# RSL15 register map
Vendor: ONSemiconductor; Series: RSL15 Series; File version: 1.0
CPU: CM33 r0p4, little endian, MPU, FPU, 3 interrupt priority bits
Registers are 32-bit, read-write, reset 0x0 unless marked. A register's access mark holds for its fields unless they carry their own. Offsets are from the block's base; [hi:lo] are bit positions; {n}, {i} and the like mark numbered series.

## MPU — Memory Protection Unit
Base 0xE000ED90
0x00 MPU_TYPE ro reset 0x400 — Indicates how many regions the MPU for the selected security state supports
  [15:8] NBR_OF_REGION — Number of regions
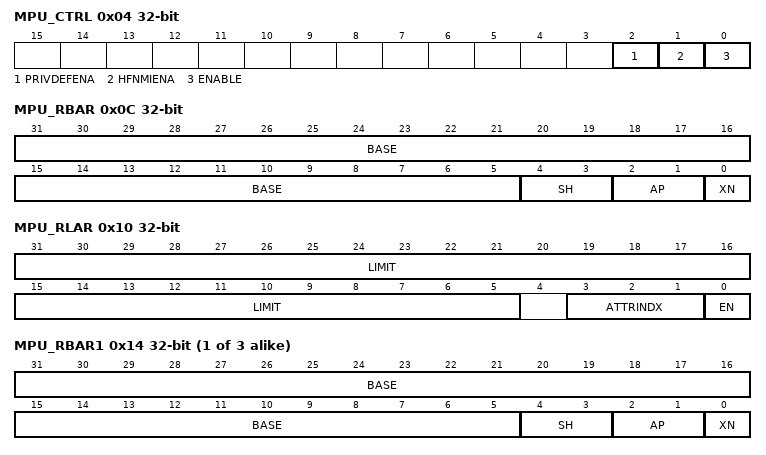
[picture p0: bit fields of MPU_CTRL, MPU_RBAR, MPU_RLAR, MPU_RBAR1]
0x04 MPU_CTRL — MPU control register
  [2] PRIVDEFENA — Privileged default enable
    0=DEFAULT_MEM_MAP_DISABLED (Disables use of the default memory map. Any memory access to a location that is not covered by any enabled region causes a fault); 1=DEFAULT_MEM_MAP_ENABLED (Enables use of the default memory map as a background region for privileged software accesses)
  [1] HFNMIENA — Hard fault and NMI enable
    0=MPU_DISABLED_FOR_HF_NMI (MPU is disabled during HardFault and NMI handlers, regardless of the value of the ENABLE bit); 1=MPU_ENABLED_FOR_HF_NMI (The MPU is enabled during HardFault and NMI handlers)
  [0] ENABLE — Enable the MPU
    0=MPU_DISABLED (MPU is disabled); 1=MPU_ENABLED (MPU is enabled)
0x08 MPU_RNR ro — MPU Region Number Register
  [7:0] REGION — Region number
0x0C MPU_RBAR — MPU Region Base Address Register
  [31:5] BASE — Base address
  [4:3] SH — Shareability
    0=NON_SHAREABLE; 2=OUTER_SHAREABLE; 3=INNER_SHAREABLE
  [2:1] AP — Access permissions
    0=RW_PRIVILEGED_CODE_ONLY (Read/write by privileged code only); 1=RW_PRIVILEGED_LEVEL (Read/write by any privilege level); 2=R_PRIVILEGED_CODE_ONLY (Read-only by privileged code only); 3=R_PRIVILEGED_LEVEL (Read-only by any privilege level)
  [0] XN — Execute never
    0=EXEC_PERMITED (Execution only permitted if read permitted); 1=EXEC_NOT_PERMITTED (Execution not permitted)
0x10 MPU_RLAR — MPU Region Limit Address Register
  [31:5] LIMIT — Limit address
  [3:1] ATTRINDX — Attribute index
  [0] EN — Region enable
    0=REGION_DISABLED; 1=REGION_ENABLED
{0xC+8i} MPU_RBAR{i} (i=1..3) — MPU Region {i} Base Address Register
  [31:5] BASE — Base address
  [4:3] SH — Shareability
  [2:1] AP — Access permissions
  [0] XN — Execute never
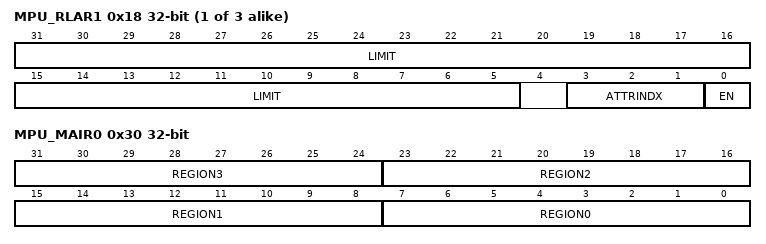
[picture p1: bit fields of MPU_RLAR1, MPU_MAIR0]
{0x10+8i} MPU_RLAR{i} (i=1..3) — MPU Region {i} Limit Address Register
  [31:5] LIMIT — Limit address
  [3:1] ATTRINDX — Attribute index
  [0] EN — Region enable
0x30 MPU_MAIR0 — MPU Memoryattribute Indirection Register 0
  [8n+7:8n] REGION{n} (n=0..3) — Memory attribute encoding for MPU regions {n}

## SAU — Security Attribution Unit
Base 0xE000EDD0
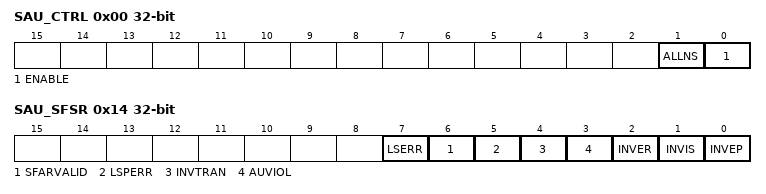
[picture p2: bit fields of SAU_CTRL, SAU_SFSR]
0x00 SAU_CTRL — SAU Control Register
  [1] ALLNS — All non-secure
    0=MEM_AS_SECURE (Memory is marked as Secure and is not Non-secure callable); 1=MEM_AS_NON_SECURE (Memory is marked as Non-secure)
  [0] ENABLE — Enable the SAU
    0=SAU_DISABLED (The SAU is disabled); 1=SAU_ENABLED (The SAU is enabled)
0x04 SAU_TYPE ro reset 0x4
  [7:0] NBR_OF_REGION — Number of region implemented by the SAU
    4=FOUR_SAU_REGIONS (The number of implemented SAU regions)
0x08 SAU_RNR — SAU Region Number Register
  [7:0] SEL_REGION — Selects the region currently accessed by SAU_RBAR and SAU_RLAR
0x0C SAU_RBAR — SAU Region Base Address Register
  [31:5] BASE_ADDRESS
0x10 SAU_RLAR — SAU Region Limit Address Register
  [31:5] LIMIT_ADDRESS
0x14 SAU_SFSR ro — Secure Fault Status Register
  [7] LSERR — Lazy state error flag
  [6] SFARVALID — Secure fault address valid
  [5] LSPERR — Lazy state preservation error flag
  [4] INVTRAN — Invalid transition flag
  [3] AUVIOL — Attribution unit violation flag
  [2] INVER — Invalid exception return flag
  [1] INVIS — Invalid integrity signature flag
  [0] INVEP — Invalid entry point
0x18 SAU_SFAR ro — Secure Fault Address Register
  [31:0] ADDRESS

## DEBUG — Debug Control Block
Base 0xE000EDF0
0x00 DEBUG_DHCSR reset 0x1 (reset mask 0x71F002F) — Debug Halting Control and Status Register
  [26] S_RESART_S ro — Restart sticky status
  [25] S_RESET_ST ro — Core has been reset or is being rest. Bit is cleared on read.
  [24] S_RETIRE_ST ro — Retire sticky status
  [20] S_SDE ro — Secure debug enable. Indicates whether Secure invasive debug is allowed
  [19] S_LOCKUP ro — Indicates if core is in lockup state
  [18] S_SLEEP ro — Indicates if core is in sleep mode
  [17] S_HALT ro — Indicates is core is halted
  [31:16] DBGKEY wo — Debug key must be written to this field in order to write the rest of the register
    0xA05F=DEBUG_HALT_KEY (Key to unlock DEBUG_DHCSR register)
  [16] S_REGRDY ro — Indicates register read/write operation is completed
  [5] C_SNAPSTALL — Set to break a stalled memory access
  [3] C_MASKINTS — Mask interrupts while stepping
  [2] C_STEP — Single step the processor
  [1] C_HALT — Halt the processor
  [0] C_DEBUGEN — Enable halt mode debugging
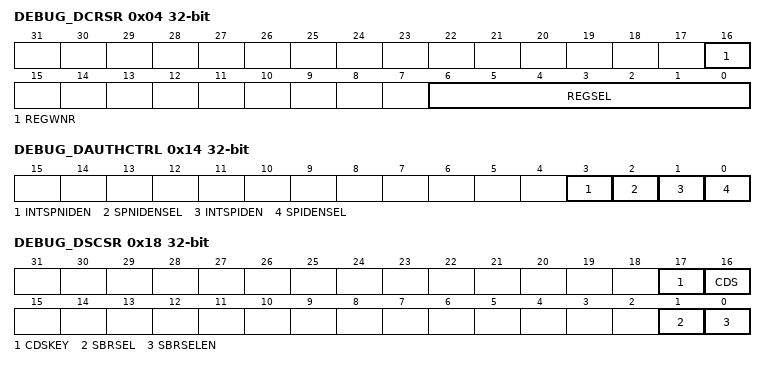
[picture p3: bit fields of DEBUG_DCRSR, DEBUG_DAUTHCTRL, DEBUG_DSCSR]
0x04 DEBUG_DCRSR reset not defined — Debug Core Register Selector Register
  [16] REGWNR wo — Indicates direction of register transfer
    0=REGWNR_READ (Indicates register read); 1=REGWNR_WRITE (Indicates register write)
  [6:0] REGSEL wo — Indicates register to be accessed
    {v}=REGSEL_R{v} (Select R{v}) (v=0..12); 13=REGSEL_SP (Select current stack pointer); 14=REGSEL_LR (Select LR); 15=REGSEL_DRA (Select Debug Return Address); 16=REGSEL_XPSR (Select xPSR/flags); 17=REGSEL_MSP (Select main stack pointer); 18=REGSEL_PSP (Select process stack pointer); 20=REGSEL_SPECREG (Access other registers including control, FAULTMASK, BASEPRI and PRIMASK); 24=REGSEL_MSP_NS (Select non-secure main stack pointer); 25=REGSEL_PSP_NS (Select non-secure process stack pointer); 26=REGSEL_MPS_S (Select secure main stack pointer); 27=REGSEL_PSP_S (Select secure process stack pointer); 28=REGSEL_MSPLIM_S (Select secure main stack limit); 29=REGSEL_PSPLIM_S (Select secure process stack limit); 30=REGSEL_MSPLIM_NS (Select non-secure main stack limit); 31=REGSEL_PSPLIM_NS (Select non-secure process stack limit); 33=REGSEL_FPSCR (Select Floating Point register); 34=REGSEL_SPECREG_S (Access other registers including control, FAULTMASK, BASEPRI and PRIMASK when S_SDE = 1); {v}=REGSEL_S{v-64} (Select Floating point register S{v-64}) (v=64..95)
0x08 DEBUG_DCRDR — Debug Core Register Data Register
  [31:0] DEBUG_REGDATA — Register read/write data for debugging
0x0C DEBUG_DEMCR access not given reset not defined — Debug Exception and Monitor Control Register
0x14 DEBUG_DAUTHCTRL ro — Debug Authentication Control Regiser
  [3] INTSPNIDEN — Internal Secure non-invasive debug enable
  [2] SPNIDENSEL — Secure non-invasive debug enable select
  [1] INTSPIDEN — Internal Secure invasive debug enable
  [0] SPIDENSEL — Secure invasive debug enable select
0x18 DEBUG_DSCSR (reset mask 0x10003) — Debug Security Control and Status Register
  [17] CDSKEY wo — CDS write-enable key
    0=CDS_NOT_IGNORED (Concurrent write to CDS not ignored); 1=CDS_IGNORED (Concurrent write to CDS ignored)
  [16] CDS — Current domain secure
    0=PE_IS_IN_NON_SECURE (PE is in Non-secure state); 1=PE_IS_IN_SECURE (PE is in Secure state)
  [1] SBRSEL — Secure banked register select
  [0] SBRSELEN — Secure banked register select enable

## SIG — Software Interrupt Generation
Base 0xE000EF00
0x00 SIG_STIR reset not defined — Software Triggered Interrupt Register
  [8:0] INTID wo — Indicates the interrupt to be pended

## FPE — Floating-Point Extension
Base 0xE000EF34
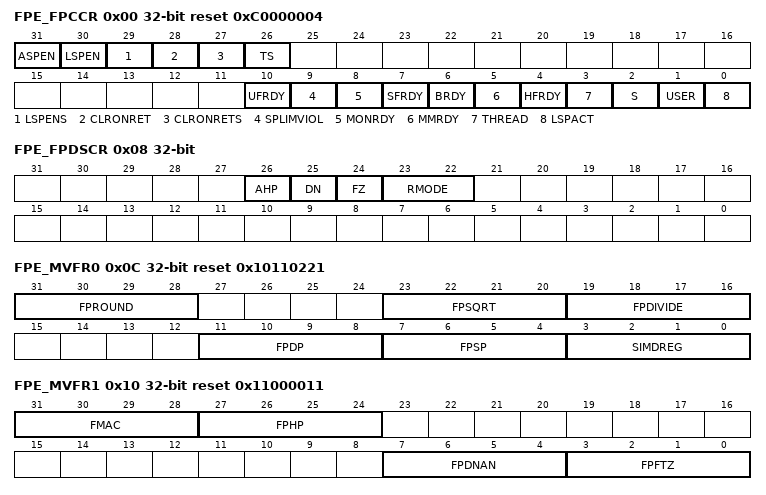
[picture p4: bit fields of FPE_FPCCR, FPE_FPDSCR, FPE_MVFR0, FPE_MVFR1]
0x00 FPE_FPCCR reset 0xC0000004 — Floating-Point Context Control Register
  [31] ASPEN — When this bit is set to 1, execution of a floating-point instruction sets the CONTROL.FPCA bit to 1
  [30] LSPEN — Enable lazy contect save of FP state
  [29] LSPENS — This bit controls whether the LSPEN bit is writable from the Non-secure state
  [28] CLRONRET — Clear floating point caller saved register on exception return
  [27] CLRONRETS — CLRONRET secure only
  [26] TS — Threat FP registers as Secure enable
  [10] UFRDY — Indicates whether the software executing when the processor allocated the floating-point stack frame was able to set the Usage Fault exeption to pending.
  [9] SPLIMVIOL — This bit is banked between the Security states and indicates whether the floating-point context violates the stack pointer limit that was active when lazy state preservation was activated.
  [8] MONRDY — Indicates whether the software executing when the processor allocated the floating-point stack frame was able to set the debug monitor execption to pending.
  [7] SFRDY — Indicates whether the software executing when the processor allocated the floating-point stack frame was able to set the secure fault exception to pending.
  [6] BRDY — Indicates whether the software executing when the processor allocated the floating-point stack frame was able to set the bus fault exception to pending.
  [5] MMRDY — Indicates whether the software executing when the processor allocated the floating-point stack frame was able to set the Mem Manage exception to pending.
  [4] HFRDY — Indicates whether the software executing when the processor allocated the floating-point stack frame was able to set the Hard fault exception to pending.
  [3] THREAD — Indicates the processor mode when it allocated the floating-point stack frame.
  [2] S — Security status of the floating-point context
  [1] USER — Indicates the privilege level of the software executing when the processor allocated the floating-point stack frame
  [0] LSPACT — Indicates whether lazy preservation of the floating-point state is active.
0x04 FPE_FPCAR — Floating-Point Context Address Register
  [31:3] ADDRESS — The location of the unpopulated floating-point register space allocated on an exception stack frame.
0x08 FPE_FPDSCR — Floating-Point Default Status Control Register
  [26] AHP — Alternative half-precision.
  [25] DN — Default NaN
  [24] FZ — Flush-to-zero
  [23:22] RMODE — Rounding mode
0x0C FPE_MVFR0 reset 0x10110221 — Media and VFP Feature Register 0
  [31:28] FPROUND — All rounding modes supported
  [23:20] FPSQRT — Floating-point square root
  [19:16] FPDIVIDE — Floating-point divide
  [11:8] FPDP — Floating-point double-precision
  [7:4] FPSP — Floating-point single-precision
  [3:0] SIMDREG — SIMD registers. Indicates size of floating-point extension register file. (15*64 bit registers)
0x10 FPE_MVFR1 reset 0x11000011 — Media and VFP Feature Register 1
  [31:28] FMAC — Fused multiply accumulate
  [27:24] FPHP — Floating-point half-precision
  [7:4] FPDNAN — Floating-point default NaN
  [3:0] FPFTZ — Floating-point flush-to-zero
0x14 FPE_MVFR2 reset 0x40 — Media and VFP Feature Register 2
  [7:4] FPMISC — Floating-point miscellaneous
